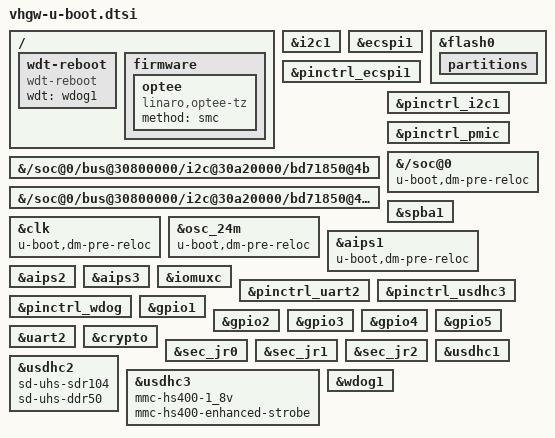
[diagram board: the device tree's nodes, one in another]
// SPDX-License-Identifier: GPL-2.0+
/*
 * Copyright 2019, 2021 NXP
 */

/ {
	wdt-reboot {
		compatible = "wdt-reboot";
		wdt = <&wdog1>;
		u-boot,dm-spl;
	};
	firmware {
		optee {
			compatible = "linaro,optee-tz";
			method = "smc";
		};
	};
};

&i2c1 {
	u-boot,dm-spl;
};

&ecspi1 {
	u-boot,dm-spl;
};

&flash0 {
	u-boot,dm-spl;
	partitions {
		u-boot,dm-spl;
	};
};

&pinctrl_ecspi1 {
	u-boot,dm-spl;
};

&{/soc@0/bus@30800000/i2c@30a20000/bd71850@4b} {
	u-boot,dm-spl;
};

&{/soc@0/bus@30800000/i2c@30a20000/bd71850@4b/regulators} {
	u-boot,dm-spl;
};

&pinctrl_i2c1 {
	u-boot,dm-spl;
};

&pinctrl_pmic {
	u-boot,dm-spl;
};

&{/soc@0} {
	u-boot,dm-pre-reloc;
	u-boot,dm-spl;
};

&spba1 {
	u-boot,dm-spl;
};

&clk {
	u-boot,dm-spl;
	u-boot,dm-pre-reloc;
	/delete-property/ assigned-clocks;
	/delete-property/ assigned-clock-parents;
	/delete-property/ assigned-clock-rates;
};

&osc_24m {
	u-boot,dm-spl;
	u-boot,dm-pre-reloc;
};

&aips1 {
	u-boot,dm-spl;
	u-boot,dm-pre-reloc;
};

&aips2 {
	u-boot,dm-spl;
};

&aips3 {
	u-boot,dm-spl;
};

&iomuxc {
	u-boot,dm-spl;
};

&pinctrl_uart2 {
	u-boot,dm-spl;
};

&pinctrl_usdhc3 {
	u-boot,dm-spl;
};

&pinctrl_wdog {
	u-boot,dm-spl;
};

&gpio1 {
	u-boot,dm-spl;
};

&gpio2 {
	u-boot,dm-spl;
};

&gpio3 {
	u-boot,dm-spl;
};

&gpio4 {
	u-boot,dm-spl;
};

&gpio5 {
	u-boot,dm-spl;
};

&uart2 {
	u-boot,dm-spl;
};

&crypto {
	u-boot,dm-spl;
};

&sec_jr0 {
	u-boot,dm-spl;
};

&sec_jr1 {
	u-boot,dm-spl;
};

&sec_jr2 {
	u-boot,dm-spl;
};

&usdhc1 {
	u-boot,dm-spl;
};

&usdhc2 {
	u-boot,dm-spl;
	sd-uhs-sdr104;
	sd-uhs-ddr50;
};

&usdhc3 {
	u-boot,dm-spl;
	mmc-hs400-1_8v;
	mmc-hs400-enhanced-strobe;
};

&wdog1 {
	u-boot,dm-spl;
};
